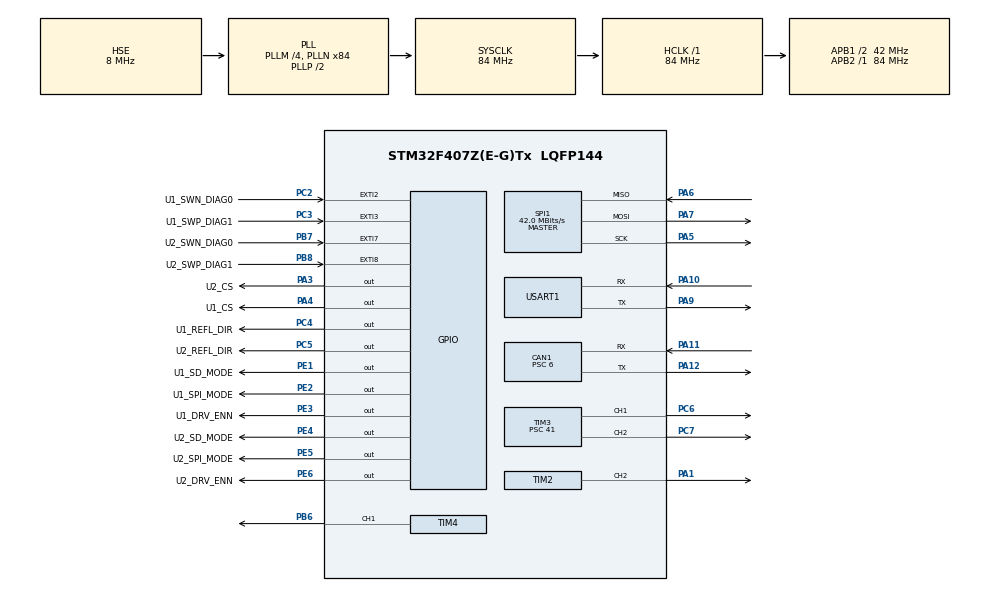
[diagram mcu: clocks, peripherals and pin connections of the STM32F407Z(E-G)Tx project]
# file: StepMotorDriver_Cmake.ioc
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CAN1.ABOM=ENABLE
CAN1.BS1=CAN_BS1_11TQ
CAN1.BS2=CAN_BS2_2TQ
CAN1.CalculateBaudRate=500000
CAN1.CalculateTimeBit=2000
CAN1.CalculateTimeQuantum=142.85714285714286
CAN1.Mode=CAN_MODE_NORMAL
CAN1.Prescaler=6
CAN1.RFLM=DISABLE
CAN1.SJW=CAN_SJW_2TQ
CAN1.TXFP=DISABLE
IWDG.Prescaler=IWDG_PRESCALER_32
IWDG.Reload=1000
Mcu.Family=STM32F4
Mcu.Name=STM32F407Z(E-G)Tx
Mcu.Package=LQFP144
NVIC.CAN1_RX0_IRQn=true\:0\:0\:true\:false\:true\:true\:true\:true
NVIC.PriorityGroup=NVIC_PRIORITYGROUP_4
PA1.Signal=S_TIM2_CH2
PA10.Mode=Asynchronous
PA10.Signal=USART1_RX
PA11.Mode=CAN_Activate
PA11.Signal=CAN1_RX
PA12.Mode=CAN_Activate
PA12.Signal=CAN1_TX
PA13.Mode=Serial_Wire
PA13.Signal=SYS_JTMS-SWDIO
PA14.Mode=Serial_Wire
PA14.Signal=SYS_JTCK-SWCLK
PA3.GPIO_Label=U2_CS
PA3.Signal=GPIO_Output
PA4.GPIO_Label=U1_CS
PA4.Signal=GPIO_Output
PA5.Mode=Full_Duplex_Master
PA5.Signal=SPI1_SCK
PA6.Mode=Full_Duplex_Master
PA6.Signal=SPI1_MISO
PA7.Mode=Full_Duplex_Master
PA7.Signal=SPI1_MOSI
PA9.Mode=Asynchronous
PA9.Signal=USART1_TX
PB6.Signal=S_TIM4_CH1
PB7.GPIO_Label=U2_SWN_DIAG0
PB7.Signal=GPXTI7
PB8.GPIO_Label=U2_SWP_DIAG1
PB8.Signal=GPXTI8
PC2.GPIO_Label=U1_SWN_DIAG0
PC2.Signal=GPXTI2
PC3.GPIO_Label=U1_SWP_DIAG1
PC3.Signal=GPXTI3
PC4.GPIO_Label=U1_REFL_DIR
PC4.GPIO_PuPd=GPIO_PULLDOWN
PC4.Signal=GPIO_Output
PC5.GPIO_Label=U2_REFL_DIR
PC5.GPIO_PuPd=GPIO_PULLDOWN
PC5.Signal=GPIO_Output
PC6.Signal=S_TIM3_CH1
PC7.Signal=S_TIM3_CH2
PE1.GPIO_Label=U1_SD_MODE
PE1.Signal=GPIO_Output
PE2.GPIO_Label=U1_SPI_MODE
PE2.Signal=GPIO_Output
PE3.GPIO_Label=U1_DRV_ENN
PE3.PinState=GPIO_PIN_SET
PE3.Signal=GPIO_Output
PE4.GPIO_Label=U2_SD_MODE
PE4.Signal=GPIO_Output
PE5.GPIO_Label=U2_SPI_MODE
PE5.Signal=GPIO_Output
PE6.GPIO_Label=U2_DRV_ENN
PE6.PinState=GPIO_PIN_SET
PE6.Signal=GPIO_Output
PH0-OSC_IN.Mode=HSE-External-Oscillator
PH0-OSC_IN.Signal=RCC_OSC_IN
PH1-OSC_OUT.Mode=HSE-External-Oscillator
PH1-OSC_OUT.Signal=RCC_OSC_OUT
ProjectManager.HeapSize=0x200
ProjectManager.StackSize=0x400
ProjectManager.TargetToolchain=CMake
RCC.48MHZClocksFreq_Value=42000000
RCC.AHBFreq_Value=84000000
RCC.APB1CLKDivider=RCC_HCLK_DIV2
RCC.APB1Freq_Value=42000000
RCC.APB1TimFreq_Value=84000000
RCC.APB2Freq_Value=84000000
RCC.APB2TimFreq_Value=84000000
RCC.CortexFreq_Value=84000000
RCC.HCLKFreq_Value=84000000
RCC.HSE_VALUE=8000000
RCC.HSICalibrationValue=8
RCC.HSI_VALUE=16000000
RCC.LSE_VALUE=32768
RCC.PLLM=4
RCC.PLLN=84
RCC.PLLSourceVirtual=RCC_PLLSOURCE_HSE
RCC.SYSCLKFreq_VALUE=84000000
RCC.SYSCLKSource=RCC_SYSCLKSOURCE_PLLCLK
RCC.VCOOutputFreq_Value=168000000
SH.S_TIM2_CH2.0=TIM2_CH2,PWM Generation2 CH2
SH.S_TIM3_CH1.0=TIM3_CH1,PWM Generation1 CH1
SH.S_TIM3_CH2.0=TIM3_CH2,PWM Generation2 CH2
SH.S_TIM4_CH1.0=TIM4_CH1,PWM Generation1 CH1
SPI1.CalculateBaudRate=42.0 MBits/s
SPI1.Direction=SPI_DIRECTION_2LINES
SPI1.Mode=SPI_MODE_MASTER
SPI1.VirtualType=VM_MASTER
TIM2.Channel-PWM\ Generation2\ CH2=TIM_CHANNEL_2
TIM2.Period=9999
TIM2.Prescaler=8399
TIM3.Channel-PWM\ Generation1\ CH1=TIM_CHANNEL_1
TIM3.Channel-PWM\ Generation2\ CH2=TIM_CHANNEL_2
TIM3.OCMode_PWM-PWM\ Generation1\ CH1=TIM_OCMODE_PWM1
TIM3.Prescaler=41
TIM4.Channel-PWM\ Generation1\ CH1=TIM_CHANNEL_1
TIM4.Period=5
TIM4.Prescaler=0
USART1.VirtualMode=VM_ASYNC
VP_IWDG_VS_IWDG.Mode=IWDG_Activate
VP_TIM2_VS_ClockSourceINT.Mode=Internal
VP_TIM3_VS_OPM.Mode=OPM_bit
VP_TIM4_VS_ClockSourceINT.Mode=Internal
board=custom

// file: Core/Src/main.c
/* USER CODE BEGIN Header */
/**
  ******************************************************************************
  * @file           : main.c
  * @brief          : Main program body
  ******************************************************************************
  * @attention
  *
  * Copyright (c) 2026 STMicroelectronics.
  * All rights reserved.
  *
  * This software is licensed under terms that can be found in the LICENSE file
  * in the root directory of this software component.
  * If no LICENSE file comes with this software, it is provided AS-IS.
  *
  ******************************************************************************
  */
/* USER CODE END Header */
#include "main.h"
#include "can.h"
#include "iwdg.h"
#include "spi.h"
#include "tim.h"
#include "usart.h"
#include "gpio.h"

/* USER CODE BEGIN Includes */
#include "elaco_main.h"
#include "cmd_queue.h"
#include "tmc5160.h"
/* USER CODE END Includes */

void SystemClock_Config(void);

int main(void)
{

  /* MCU Configuration--------------------------------------------------------*/

  /* Reset of all peripherals, Initializes the Flash interface and the Systick. */
  HAL_Init();

  /* Configure the system clock */
  SystemClock_Config();

  /* Initialize all configured peripherals */
  MX_GPIO_Init();
  MX_CAN1_Init();
  MX_TIM2_Init();
  MX_TIM4_Init();
  MX_IWDG_Init();
  MX_SPI1_Init();
  MX_TIM3_Init();
  MX_USART1_UART_Init();
  /* USER CODE BEGIN 2 */

  elaco_main_proc(); // 主循环
  /* USER CODE END 2 */

  /* Infinite loop */
  while (1)
  {

  }
}

void SystemClock_Config(void)
{
  RCC_OscInitTypeDef RCC_OscInitStruct = {0};
  RCC_ClkInitTypeDef RCC_ClkInitStruct = {0};

  /** Configure the main internal regulator output voltage
  */
  __HAL_RCC_PWR_CLK_ENABLE();
  __HAL_PWR_VOLTAGESCALING_CONFIG(PWR_REGULATOR_VOLTAGE_SCALE1);

  /** Initializes the RCC Oscillators according to the specified parameters
  * in the RCC_OscInitTypeDef structure.
  */
  RCC_OscInitStruct.OscillatorType = RCC_OSCILLATORTYPE_LSI|RCC_OSCILLATORTYPE_HSE;
  RCC_OscInitStruct.HSEState = RCC_HSE_ON;
  RCC_OscInitStruct.LSIState = RCC_LSI_ON;
  RCC_OscInitStruct.PLL.PLLState = RCC_PLL_ON;
  RCC_OscInitStruct.PLL.PLLSource = RCC_PLLSOURCE_HSE;
  RCC_OscInitStruct.PLL.PLLM = 4;
  RCC_OscInitStruct.PLL.PLLN = 84;
  RCC_OscInitStruct.PLL.PLLP = RCC_PLLP_DIV2;
  RCC_OscInitStruct.PLL.PLLQ = 4;
  if (HAL_RCC_OscConfig(&RCC_OscInitStruct) != HAL_OK)
  {
    Error_Handler();
  }

  /** Initializes the CPU, AHB and APB buses clocks
  */
  RCC_ClkInitStruct.ClockType = RCC_CLOCKTYPE_HCLK|RCC_CLOCKTYPE_SYSCLK
                              |RCC_CLOCKTYPE_PCLK1|RCC_CLOCKTYPE_PCLK2;
  RCC_ClkInitStruct.SYSCLKSource = RCC_SYSCLKSOURCE_PLLCLK;
  RCC_ClkInitStruct.AHBCLKDivider = RCC_SYSCLK_DIV1;
  RCC_ClkInitStruct.APB1CLKDivider = RCC_HCLK_DIV2;
  RCC_ClkInitStruct.APB2CLKDivider = RCC_HCLK_DIV1;

  if (HAL_RCC_ClockConfig(&RCC_ClkInitStruct, FLASH_LATENCY_2) != HAL_OK)
  {
    Error_Handler();
  }
}

void Error_Handler(void)
{
  __disable_irq();
  while (1)
  {
  }
}
